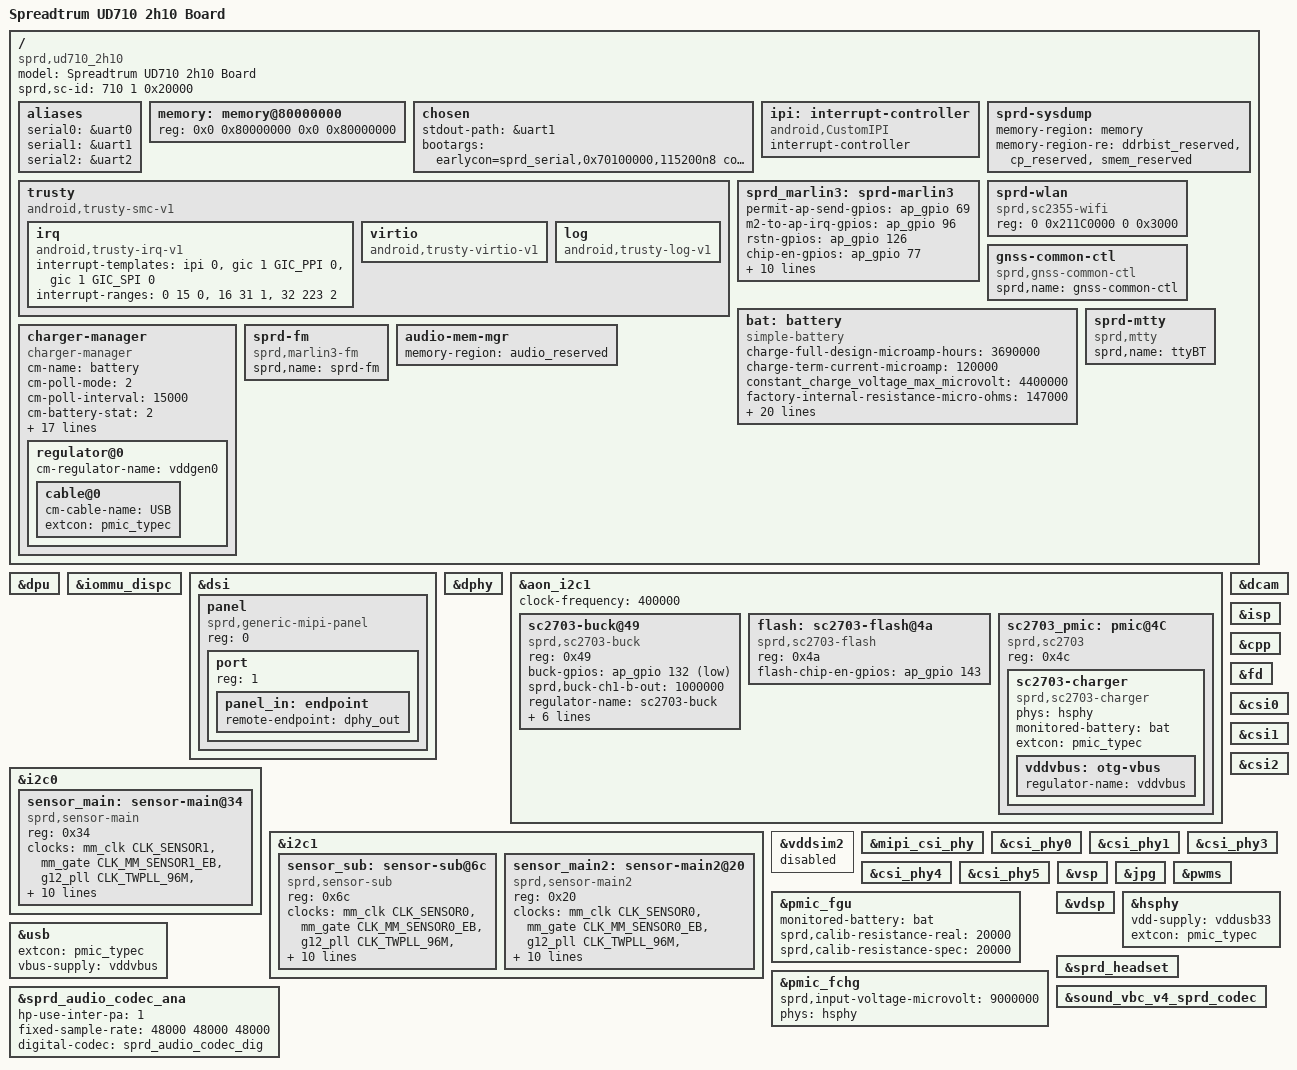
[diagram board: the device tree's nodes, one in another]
/*
 * Spreadtrum Roc1 board DTS file
 *
 * Copyright (C) 2018, Spreadtrum Communications Inc.
 *
 * This file is licensed under a dual GPLv2 or X11 license.
 */
/dts-v1/;

#include <dt-bindings/gpio/gpio.h>

#include "ud710.dtsi"
#include "ud710-2h10-common.dtsi"
#include "ud710-2h10-modem.dtsi"
#include "sprd-sound-fe-be.dtsi"
#include "sc2730.dtsi"
#include "lcd/lcd_td4310_truly_mipi_fhd.dtsi"

/ {
	model = "Spreadtrum UD710 2h10 Board";

	compatible = "sprd,ud710_2h10", "sprd,ud710";

	sprd,sc-id = <710 1 0x20000>;

	aliases {
		serial0 = &uart0;
		serial1 = &uart1;
		serial2 = &uart2;
	};

	memory: memory@80000000 {
		device_type = "memory";
		reg = <0x0 0x80000000 0x0 0x80000000>;
	};

	chosen {
		stdout-path = &uart1;
		bootargs = "earlycon=sprd_serial,0x70100000,115200n8 console=ttyS1,115200n8 loglevel=8 maxcpus=1 init=/init root=/dev/mmcblk0p30 rootfstype=ext4 rw rootwait androidboot.hardware=ud710_2h10 androidboot.selinux=permissive";
	};

	ipi: interrupt-controller {
		compatible = "android,CustomIPI";
		#interrupt-cells = <1>;
		interrupt-controller;
	};

	trusty {
		compatible = "android,trusty-smc-v1";

		irq {
			compatible = "android,trusty-irq-v1";
			interrupt-templates = <&ipi 0>,
						<&gic 1 GIC_PPI 0>,
						<&gic 1 GIC_SPI 0>;
			interrupt-ranges = < 0  15 0>,
						<16  31 1>,
						<32 223 2>;
		};

		virtio {
			compatible = "android,trusty-virtio-v1";
		};

		log {
			compatible = "android,trusty-log-v1";
		};
	};

	sprd-sysdump {
		memory-region = <&memory>;
		memory-region-re = <&ddrbist_reserved>, <&cp_reserved>, <&smem_reserved>;
	};

	sprd_marlin3: sprd-marlin3 {
		permit-ap-send-gpios = <&ap_gpio 69 0>;
		m2-to-ap-irq-gpios = <&ap_gpio 96 0>;
		rstn-gpios = <&ap_gpio 126 0>;
		chip-en-gpios = <&ap_gpio 77 0>;
		dvdd12-supply = <&vddmem>;
		avdd12-supply = <&vddgen1>;
		avdd33-supply = <&vddwifipa>;
		dcxo18-supply = <&vddldo0>;
		common_chip_en;
		sprd,wait-ge2-disabled;
		adma_tx_enable;
		adma_rx_enable;
		pwrseq_disable;
		post-power-on-delay-ms = <20>;
	};

	sprd-wlan {
		compatible = "sprd,sc2355-wifi";
		reg = <0 0x211C0000 0 0x3000>;
		reg-names = "PAM_WIFI_REG_BASE_REMAP";
	};

	gnss-common-ctl {
		compatible = "sprd,gnss-common-ctl";
		sprd,name = "gnss-common-ctl";
	};

	bat: battery {
		compatible = "simple-battery";
		charge-full-design-microamp-hours = <3690000>;
		charge-term-current-microamp = <120000>;
		constant_charge_voltage_max_microvolt = <4400000>;
		factory-internal-resistance-micro-ohms = <147000>;
		voltage-min-design-microvolt = <3450000>;
		ocv-capacity-celsius = <20>;
		ocv-capacity-table-0 = <4360000 100>, <4317000 95>, <4258000 90>,
					<4200000 85>, <4145000 80>, <4092000 75>,
					<4047000 70>, <3990000 65>, <3955000 60>,
					<3900000 55>, <3861000 50>, <3834000 45>,
					<3813000 40>, <3796000 35>, <3783000 30>,
					<3770000 25>, <3752000 20>, <3730000 15>,
					<3698000 10>, <3687000 5>, <3400000 0>;
		voltage-temp-table = <1052000 750>, <953000 800>, <858000 850>,
				      <762000 900>, <671000 950>,<584000 1000>,
				      <504000 1050>, <434000 1100>, <372000 1150>,
				      <318000 1200>,<271000 1250>, <234000 1300>,
				      <198000 1350>, <165000 1400>, <140000 1450>,
				      <119000 1500>, <104000 1550>, <88000 1600>;
		charge-sdp-current-microamp = <500000 500000>;
		charge-dcp-current-microamp = <2000000 3000000>;
		charge-cdp-current-microamp = <1500000 1500000>;
		charge-unknown-current-microamp = <500000 500000>;
	};

	charger-manager {
		compatible = "charger-manager";
		cm-name = "battery";
		cm-poll-mode = <2>;
		cm-poll-interval = <15000>;
		cm-battery-stat = <2>;

		cm-fullbatt-vchkdrop-ms = <30000>;
		cm-fullbatt-vchkdrop-volt = <60000>;
		cm-fullbatt-voltage = <4380000>;
		cm-fullbatt-current = <120000>;
		cm-fullbatt-capacity = <100>;

		cm-num-chargers = <1>;
		cm-chargers = "sc2703_charger";
		cm-fuel-gauge = "sc27xx-fgu";

		/* in deci centigrade */
		cm-battery-cold = <50>;
		cm-battery-cold-in-minus;
		cm-battery-hot = <800>;
		cm-battery-temp-diff = <100>;

		/* Allow charging for 6hr */
		cm-charging-max = <18000000>;

		/* the interval to feed charger watchdog */
		cm-wdt-interval = <60>;

		/* drop voltage in microVolts to allow shutdown */
		cm-shutdown-voltage = <3100000>;

		/* when 99% of the time is exceeded, it will be forced to 100% */
		cm-tickle-time-out = <1500>;

		/* how much time to allow capacity change */
		cm-one-cap-time = <30>;

		regulator@0 {
			cm-regulator-name = "vddgen0";
			cable@0 {
				cm-cable-name = "USB";
				extcon = <&pmic_typec>;
			};
		};
	};

	sprd-mtty {
		compatible = "sprd,mtty";
		sprd,name = "ttyBT";
	};

	sprd-fm {
		compatible = "sprd,marlin3-fm";
		sprd,name = "sprd-fm";
	};

	audio-mem-mgr {
		memory-region = <&audio_reserved>;
	};
};

&dpu {
	status = "okay";
};

&iommu_dispc {
	status = "okay";
};

&dsi {
	status = "okay";
	#address-cells = <1>;
	#size-cells = <0>;

	panel {
		compatible = "sprd,generic-mipi-panel";
		#address-cells = <1>;
		#size-cells = <0>;
		reg = <0>;

		port {
			reg = <1>;
			panel_in: endpoint {
				remote-endpoint = <&dphy_out>;
			};
		};
	};
};


&dphy {
	status = "okay";
};

&aon_i2c1 {
	status = "okay";
	clock-frequency = <400000>;

	sc2703-buck@49 {
		compatible = "sprd,sc2703-buck";
		reg = <0x49>;
		buck-gpios = <&ap_gpio 132 GPIO_ACTIVE_LOW>;

		sprd,buck-ch1-b-out = <1000000>;

		regulator-name = "sc2703-buck";
		regulator-min-microvolt = < 300000>;
		regulator-max-microvolt = <1570000>;
		regulator-min-microamp = <5600000>;
		regulator-max-microamp = <10800000>;
		regulator-boot-on;
		regulator-always-on;
	};

	flash: sc2703-flash@4a {
		compatible = "sprd,sc2703-flash";
		reg = <0x4a>;
		flash-chip-en-gpios = <&ap_gpio 143 0>;
	};

	sc2703_pmic: pmic@4C {
		compatible = "sprd,sc2703";
		reg = <0x4c>;
		sc2703-charger {
			compatible = "sprd,sc2703-charger";
			phys = <&hsphy>;
			monitored-battery = <&bat>;
			extcon = <&pmic_typec>;
			vddvbus:otg-vbus {
				regulator-name = "vddvbus";
			};
		};
	};
};

&i2c0 {
	status = "okay";

	sensor_main: sensor-main@34 {
		compatible = "sprd,sensor-main";
		reg = <0x34>;

		clock-names = "clk_src","sensor_eb",
			"clk_96m","clk_76m8",
			"clk_48m","clk_26m";
		clocks = <&mm_clk CLK_SENSOR1>,<&mm_gate CLK_MM_SENSOR1_EB>,
			<&g12_pll CLK_TWPLL_96M>,<&g12_pll CLK_TWPLL_76M8>,
			<&g12_pll CLK_TWPLL_48M>,<&ext_26m>;
		vddio-supply = <&vddcamio>;
		vddcama-supply = <&vddcama0>;
		vddcamd-supply = <&vddcamd0>;
		vddcammot-supply = <&vddcammot>;
		sprd,phyid = <0>;
		csi = <&csi0>;
		reset-gpios = <&ap_gpio 45 0>;
		power-down-gpios = <&ap_gpio 47 0>;
		/*avdd-gpios = <&ap_gpio 140 0>;*/

		status = "okay";
	};
};

&i2c1 {
	status = "okay";

	sensor_sub: sensor-sub@6c {
		compatible = "sprd,sensor-sub";
		reg = <0x6c>;

		clock-names = "clk_src","sensor_eb",
			"clk_96m","clk_76m8",
			"clk_48m","clk_26m";
		clocks = <&mm_clk CLK_SENSOR0>,<&mm_gate CLK_MM_SENSOR0_EB>,
			<&g12_pll CLK_TWPLL_96M>,<&g12_pll CLK_TWPLL_76M8>,
			<&g12_pll CLK_TWPLL_48M>,<&ext_26m>;
		vddio-supply = <&vddcamio>;
		vddcama-supply = <&vddcama1>;
		vddcamd-supply = <&vddcamd1>;
		vddcammot-supply = <&vddcammot>;
		sprd,phyid = <1>;
		csi = <&csi0>;
		reset-gpios = <&ap_gpio 44 0>;
		power-down-gpios = <&ap_gpio 46 0>;
		/*avdd-gpios = <&ap_gpio 140 0>;*/

		status = "okay";
	};

	sensor_main2: sensor-main2@20 {
		compatible = "sprd,sensor-main2";
		reg = <0x20>;

		clock-names = "clk_src","sensor_eb",
			"clk_96m","clk_76m8",
			"clk_48m","clk_26m";
		clocks = <&mm_clk CLK_SENSOR0>,<&mm_gate CLK_MM_SENSOR0_EB>,
			<&g12_pll CLK_TWPLL_96M>,<&g12_pll CLK_TWPLL_76M8>,
			<&g12_pll CLK_TWPLL_48M>,<&ext_26m>;
		vddio-supply = <&vddcamio>;
		vddcama-supply = <&vddcama1>;
		vddcamd-supply = <&vddcamd1>;
		vddcammot-supply = <&vddcammot>;
		sprd,phyid = <5>;
		csi = <&csi1>;
		reset-gpios = <&ap_gpio 41 0>;
		power-down-gpios = <&ap_gpio 40 0>;

		status = "okay";
	};
};

&vddsim2 {
	status = "disabled";
};

&dcam {
	status = "okay";
};

&isp {
	status = "okay";
};

&cpp {
	status = "okay";
};

&fd{
	status = "okay";
};

&csi0{
	status = "okay";
};

&csi1{
	status = "okay";
};

&csi2{
	status = "okay";
};

&mipi_csi_phy {
	status = "okay";
};

&csi_phy0{
	status = "okay";
};

&csi_phy1{
	status = "okay";
};

&csi_phy3{
	status = "okay";
};

&csi_phy4{
	status = "okay";
};

&csi_phy5{
	status = "okay";
};

/*&iommu_cpp{
 *	status = "okay";
 *};
 */

&pmic_fgu {
	monitored-battery = <&bat>;
	sprd,calib-resistance-real = <20000>;
	sprd,calib-resistance-spec = <20000>;
};

&pmic_fchg {
	sprd,input-voltage-microvolt = <9000000>;
	phys = <&hsphy>;
};

&vsp {
	status = "okay";
};

&jpg {
	status = "okay";
};

&pwms {
	status = "okay";
};

&vdsp {
	status = "okay";
};

&hsphy {
	vdd-supply = <&vddusb33>;
	extcon = <&pmic_typec>;
};

&usb {
	extcon = <&pmic_typec>;
	vbus-supply = <&vddvbus>;
};

&sprd_headset {
	status = "okay";
};

&sprd_audio_codec_ana {
	status = "okay";
	hp-use-inter-pa = <1>;
	fixed-sample-rate = <48000 48000 48000>;
	digital-codec = <&sprd_audio_codec_dig>;
};

&sound_vbc_v4_sprd_codec {
	status = "okay";
};
